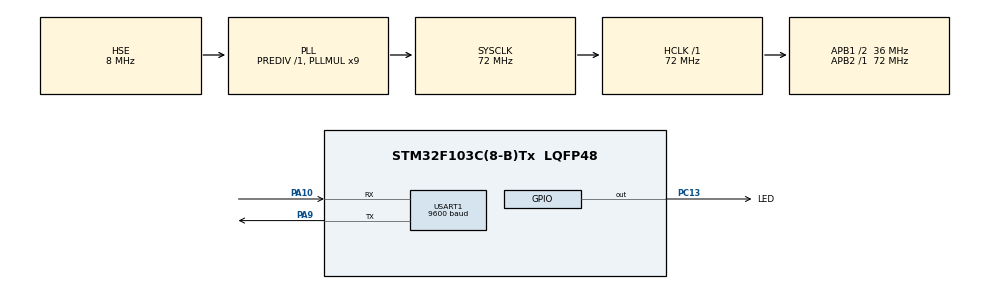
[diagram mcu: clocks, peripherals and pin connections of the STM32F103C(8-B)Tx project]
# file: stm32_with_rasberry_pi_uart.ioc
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Dma.Request0=USART1_RX
Dma.USART1_RX.0.Direction=DMA_PERIPH_TO_MEMORY
Dma.USART1_RX.0.Instance=DMA1_Channel5
Dma.USART1_RX.0.MemDataAlignment=DMA_MDATAALIGN_BYTE
Dma.USART1_RX.0.MemInc=DMA_MINC_ENABLE
Dma.USART1_RX.0.Mode=DMA_NORMAL
Dma.USART1_RX.0.PeriphDataAlignment=DMA_PDATAALIGN_BYTE
Dma.USART1_RX.0.PeriphInc=DMA_PINC_DISABLE
Dma.USART1_RX.0.Priority=DMA_PRIORITY_MEDIUM
Mcu.Family=STM32F1
Mcu.Name=STM32F103C(8-B)Tx
Mcu.Package=LQFP48
NVIC.DMA1_Channel5_IRQn=true\:0\:0\:false\:false\:true\:false\:true\:true
NVIC.PriorityGroup=NVIC_PRIORITYGROUP_4
NVIC.TIM2_IRQn=true\:0\:0\:false\:false\:true\:true\:true\:true
NVIC.USART1_IRQn=true\:0\:0\:false\:false\:true\:true\:true\:true
PA10.Mode=Asynchronous
PA10.Signal=USART1_RX
PA13.Mode=Serial_Wire
PA13.Signal=SYS_JTMS-SWDIO
PA14.Mode=Serial_Wire
PA14.Signal=SYS_JTCK-SWCLK
PA9.Mode=Asynchronous
PA9.Signal=USART1_TX
PC13-TAMPER-RTC.GPIO_Label=LED
PC13-TAMPER-RTC.Signal=GPIO_Output
PD0-OSC_IN.Mode=HSE-External-Oscillator
PD0-OSC_IN.Signal=RCC_OSC_IN
PD1-OSC_OUT.Mode=HSE-External-Oscillator
PD1-OSC_OUT.Signal=RCC_OSC_OUT
ProjectManager.HeapSize=0x200
ProjectManager.StackSize=0x400
ProjectManager.TargetToolchain=STM32CubeIDE
RCC.AHBFreq_Value=72000000
RCC.APB1CLKDivider=RCC_HCLK_DIV2
RCC.APB1Freq_Value=36000000
RCC.APB1TimFreq_Value=72000000
RCC.APB2Freq_Value=72000000
RCC.APB2TimFreq_Value=72000000
RCC.HCLKFreq_Value=72000000
RCC.PLLMUL=RCC_PLL_MUL9
RCC.PLLSourceVirtual=RCC_PLLSOURCE_HSE
RCC.SYSCLKFreq_VALUE=72000000
RCC.SYSCLKSource=RCC_SYSCLKSOURCE_PLLCLK
RCC.USBFreq_Value=72000000
TIM2.Period=500-1
TIM2.Prescaler=72-1
USART1.BaudRate=9600
USART1.VirtualMode=VM_ASYNC
VP_TIM2_VS_ClockSourceINT.Mode=Internal
board=custom

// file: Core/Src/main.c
/* USER CODE BEGIN Header */
/**
  ******************************************************************************
  * @file           : main.c
  * @brief          : Main program body
  ******************************************************************************
  * @attention
  *
  * Copyright (c) 2023 STMicroelectronics.
  * All rights reserved.
  *
  * This software is licensed under terms that can be found in the LICENSE file
  * in the root directory of this software component.
  * If no LICENSE file comes with this software, it is provided AS-IS.
  *
  ******************************************************************************
  */
/* USER CODE END Header */
#include "main.h"

/* USER CODE BEGIN Includes */
#include "string.h"
#include "math.h"
#include "stdlib.h"

#include "string.h"
#include "stdio.h"

/* USER CODE END Includes */

/* USER CODE BEGIN PD */
uint8_t r;

#define RxBuf_size 20
uint16_t k=0;
char Rx[20],s1[10],s2[10];

uint8_t rx_buffer[RxBuf_size];
uint8_t data[RxBuf_size];

char giden[50];

uint8_t Rx_data[10];

//ASCI int çevirirken basamak değerleri
uint8_t birinci_bas;
uint8_t ikinci_bas;
uint16_t ucuncu_bas;
uint16_t dorduncu_bas;
uint32_t besinci_bas;
uint32_t altinci_bas;

int gelen_deger_convetli; //Gelen ASCI int çevirlmiş hali

uint8_t idle_sayac;
uint8_t timer_sayac;
uint8_t sayac;

//UART DMA Degiskenler
#define RxBuf_SIZE   6
uint8_t len;
uint8_t	RxBuffer[RxBuf_SIZE];

extern DMA_HandleTypeDef hdma_usart1_rx;

/* USER CODE END PD */

TIM_HandleTypeDef htim2;

UART_HandleTypeDef huart1;
DMA_HandleTypeDef hdma_usart1_rx;

void SystemClock_Config(void);
static void MX_GPIO_Init(void);
static void MX_DMA_Init(void);
static void MX_USART1_UART_Init(void);
static void MX_TIM2_Init(void);

/* USER CODE BEGIN 0 */

//DMA IDLE Okuma Fonk
void HAL_UARTEx_RxEventCallback(UART_HandleTypeDef *huart, uint16_t Size)
{
	//Belirsiz Uzunlukta Veri Okuma Sağlayan Komutlar UART
  if(huart->Instance == USART1)
  {
    HAL_UARTEx_ReceiveToIdle_DMA(&huart1, RxBuffer, RxBuf_SIZE);
	__HAL_DMA_DISABLE_IT(&hdma_usart1_rx, DMA_IT_HT);
	idle_sayac++;
    for(int i=Size;i<RxBuf_SIZE;i++)
      RxBuffer[i]=0;
  }
}

void HAL_UART_RxHalfCpltCallback(UART_HandleTypeDef *huart)
{
	//UART iletişimin yarısı tamamlanınca buraya girer.
	HAL_GPIO_TogglePin(LED_GPIO_Port, LED_Pin);
}

//Interupts okuma fonk
void HAL_UART_RxCpltCallback(UART_HandleTypeDef *huart)
{
	switch(r)
	{
		case 'A': strncpy(s1,Rx,k);k=0;break;
		case 'B': strncpy(s2,Rx,k);k=0;break;
	  default: Rx[k]=r; k++;
	}
}

void HAL_TIM_PeriodElapsedCallback(TIM_HandleTypeDef* htim)
{
	if (htim == &htim2)
	{
		timer_sayac++; //Deneme Sayacı

		len = sizeof(RxBuffer)/sizeof(uint8_t);
		for(int i = 0;i<sizeof(RxBuffer)/sizeof(uint8_t);i++)
		{
			if(RxBuffer[i]==0)
			{
				len = len - 1;
			}
		}

		//Gelen Sayıyı ASCI'den int'e Çevirme Koşulları
		if(len == 1)
		{
			birinci_bas = RxBuffer[0]-'0';

			gelen_deger_convetli = birinci_bas*1;
		}
		if(len == 2)
		{
			ikinci_bas = RxBuffer[0]-'0';
			birinci_bas = RxBuffer[1]-'0';

			gelen_deger_convetli = ikinci_bas*10+birinci_bas*1;
		}
		if(len == 3)
		{
			ucuncu_bas = RxBuffer[0]-'0';
			ikinci_bas = RxBuffer[1]-'0';
			birinci_bas = RxBuffer[2]-'0';

			gelen_deger_convetli = ucuncu_bas*100+ikinci_bas*10+birinci_bas*1;
		}

		if(len == 4)
		{

			dorduncu_bas = RxBuffer[0]-'0';
			ucuncu_bas = RxBuffer[1]-'0';
			ikinci_bas = RxBuffer[2]-'0';
			birinci_bas = RxBuffer[3]-'0';

			gelen_deger_convetli = dorduncu_bas*1000+ucuncu_bas*100+ikinci_bas*10+birinci_bas*1;
		}
		if(len == 5)
		{
			besinci_bas = RxBuffer[0]-'0';
			dorduncu_bas = RxBuffer[1]-'0';
			ucuncu_bas = RxBuffer[2]-'0';
			ikinci_bas = RxBuffer[3]-'0';
			birinci_bas = RxBuffer[4]-'0';

			gelen_deger_convetli = besinci_bas*10000+dorduncu_bas*1000+ucuncu_bas*100+ikinci_bas*10+birinci_bas*1;
		}
		if(len == 6)
		{
			altinci_bas = RxBuffer[0]-'0';
			besinci_bas = RxBuffer[1]-'0';
			dorduncu_bas = RxBuffer[2]-'0';
			ucuncu_bas = RxBuffer[3]-'0';
			ikinci_bas = RxBuffer[4]-'0';
			birinci_bas = RxBuffer[5]-'0';

			gelen_deger_convetli = altinci_bas*100000+besinci_bas*10000+dorduncu_bas*1000+ucuncu_bas*100+ikinci_bas*10+birinci_bas*1;
		}

	}
}

/* USER CODE END 0 */

int main(void)
{

  /* MCU Configuration--------------------------------------------------------*/

  /* Reset of all peripherals, Initializes the Flash interface and the Systick. */
  HAL_Init();

  /* Configure the system clock */
  SystemClock_Config();

  /* Initialize all configured peripherals */
  MX_GPIO_Init();
  MX_DMA_Init();
  MX_USART1_UART_Init();
  MX_TIM2_Init();
  /* USER CODE BEGIN 2 */

  //İnterutp baslatma
  __HAL_UART_ENABLE_IT(&huart1,UART_IT_RXNE);

  //UART IDLE Kullanımı
  HAL_UARTEx_ReceiveToIdle_DMA(&huart1, RxBuffer, RxBuf_SIZE);
  __HAL_DMA_DISABLE_IT(&hdma_usart1_rx, DMA_IT_HT);

  //Timer Başlatma
  HAL_TIM_Base_Start_IT(&htim2);

  /* USER CODE END 2 */

  /* Infinite loop */
  while (1)
  {

    /* USER CODE BEGIN 3 */

	  HAL_GPIO_TogglePin(LED_GPIO_Port, LED_Pin);
	  HAL_Delay(500);
  }
  /* USER CODE END 3 */
}

void SystemClock_Config(void)
{
  RCC_OscInitTypeDef RCC_OscInitStruct = {0};
  RCC_ClkInitTypeDef RCC_ClkInitStruct = {0};

  /** Initializes the RCC Oscillators according to the specified parameters
  * in the RCC_OscInitTypeDef structure.
  */
  RCC_OscInitStruct.OscillatorType = RCC_OSCILLATORTYPE_HSE;
  RCC_OscInitStruct.HSEState = RCC_HSE_ON;
  RCC_OscInitStruct.HSEPredivValue = RCC_HSE_PREDIV_DIV1;
  RCC_OscInitStruct.HSIState = RCC_HSI_ON;
  RCC_OscInitStruct.PLL.PLLState = RCC_PLL_ON;
  RCC_OscInitStruct.PLL.PLLSource = RCC_PLLSOURCE_HSE;
  RCC_OscInitStruct.PLL.PLLMUL = RCC_PLL_MUL9;
  if (HAL_RCC_OscConfig(&RCC_OscInitStruct) != HAL_OK)
  {
    Error_Handler();
  }

  /** Initializes the CPU, AHB and APB buses clocks
  */
  RCC_ClkInitStruct.ClockType = RCC_CLOCKTYPE_HCLK|RCC_CLOCKTYPE_SYSCLK
                              |RCC_CLOCKTYPE_PCLK1|RCC_CLOCKTYPE_PCLK2;
  RCC_ClkInitStruct.SYSCLKSource = RCC_SYSCLKSOURCE_PLLCLK;
  RCC_ClkInitStruct.AHBCLKDivider = RCC_SYSCLK_DIV1;
  RCC_ClkInitStruct.APB1CLKDivider = RCC_HCLK_DIV2;
  RCC_ClkInitStruct.APB2CLKDivider = RCC_HCLK_DIV1;

  if (HAL_RCC_ClockConfig(&RCC_ClkInitStruct, FLASH_LATENCY_2) != HAL_OK)
  {
    Error_Handler();
  }
}

static void MX_TIM2_Init(void)
{

  TIM_ClockConfigTypeDef sClockSourceConfig = {0};
  TIM_MasterConfigTypeDef sMasterConfig = {0};

  htim2.Instance = TIM2;
  htim2.Init.Prescaler = 72-1;
  htim2.Init.CounterMode = TIM_COUNTERMODE_UP;
  htim2.Init.Period = 500-1;
  htim2.Init.ClockDivision = TIM_CLOCKDIVISION_DIV1;
  htim2.Init.AutoReloadPreload = TIM_AUTORELOAD_PRELOAD_DISABLE;
  if (HAL_TIM_Base_Init(&htim2) != HAL_OK)
  {
    Error_Handler();
  }
  sClockSourceConfig.ClockSource = TIM_CLOCKSOURCE_INTERNAL;
  if (HAL_TIM_ConfigClockSource(&htim2, &sClockSourceConfig) != HAL_OK)
  {
    Error_Handler();
  }
  sMasterConfig.MasterOutputTrigger = TIM_TRGO_RESET;
  sMasterConfig.MasterSlaveMode = TIM_MASTERSLAVEMODE_DISABLE;
  if (HAL_TIMEx_MasterConfigSynchronization(&htim2, &sMasterConfig) != HAL_OK)
  {
    Error_Handler();
  }

}

static void MX_USART1_UART_Init(void)
{

  huart1.Instance = USART1;
  huart1.Init.BaudRate = 9600;
  huart1.Init.WordLength = UART_WORDLENGTH_8B;
  huart1.Init.StopBits = UART_STOPBITS_1;
  huart1.Init.Parity = UART_PARITY_NONE;
  huart1.Init.Mode = UART_MODE_TX_RX;
  huart1.Init.HwFlowCtl = UART_HWCONTROL_NONE;
  huart1.Init.OverSampling = UART_OVERSAMPLING_16;
  if (HAL_UART_Init(&huart1) != HAL_OK)
  {
    Error_Handler();
  }

}

static void MX_DMA_Init(void)
{

  /* DMA controller clock enable */
  __HAL_RCC_DMA1_CLK_ENABLE();

  /* DMA interrupt init */
  /* DMA1_Channel5_IRQn interrupt configuration */
  HAL_NVIC_SetPriority(DMA1_Channel5_IRQn, 0, 0);
  HAL_NVIC_EnableIRQ(DMA1_Channel5_IRQn);

}

static void MX_GPIO_Init(void)
{
  GPIO_InitTypeDef GPIO_InitStruct = {0};

  /* GPIO Ports Clock Enable */
  __HAL_RCC_GPIOC_CLK_ENABLE();
  __HAL_RCC_GPIOD_CLK_ENABLE();
  __HAL_RCC_GPIOA_CLK_ENABLE();

  /*Configure GPIO pin Output Level */
  HAL_GPIO_WritePin(LED_GPIO_Port, LED_Pin, GPIO_PIN_RESET);

  /*Configure GPIO pin : LED_Pin */
  GPIO_InitStruct.Pin = LED_Pin;
  GPIO_InitStruct.Mode = GPIO_MODE_OUTPUT_PP;
  GPIO_InitStruct.Pull = GPIO_NOPULL;
  GPIO_InitStruct.Speed = GPIO_SPEED_FREQ_LOW;
  HAL_GPIO_Init(LED_GPIO_Port, &GPIO_InitStruct);

}

void Error_Handler(void)
{
  __disable_irq();
  while (1)
  {
  }
}
